VERSION ""

NS_ :

BS_:

BU_: DENSO_ECM COMBINATION_METER

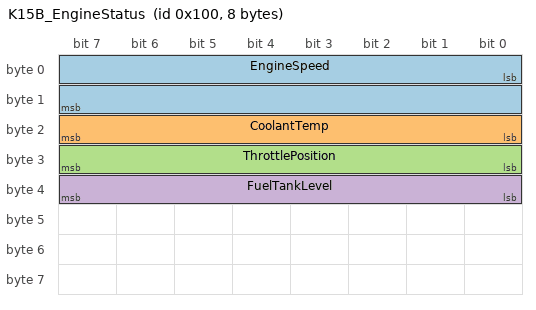
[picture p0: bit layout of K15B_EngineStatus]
BO_ 256 K15B_EngineStatus: 8 DENSO_ECM
 SG_ EngineSpeed : 0|16@1+ (0.25,0) [0|6500] "rpm" COMBINATION_METER
 SG_ CoolantTemp : 16|8@1+ (1,-40) [-40|150] "degC" COMBINATION_METER
 SG_ ThrottlePosition : 24|8@1+ (0.39215686,0) [0|100] "%" COMBINATION_METER
 SG_ FuelTankLevel : 32|8@1+ (0.5,0) [0|100] "%" COMBINATION_METER

BO_ 257 K15B_VehicleDynamics: 8 DENSO_ECM
 SG_ VehicleSpeed : 0|16@1+ (0.01,0) [0|220] "km/h" COMBINATION_METER
